AUTOSAR XML (schema 4-0-3)
standard types defined: UInt8
package /PATAC/Facility/DataTypes/Implementation
  unit NoUnit: factor-si-to-unit=1, offset-si-to-unit=0
package /PATAC/MSM/ComponentTypes
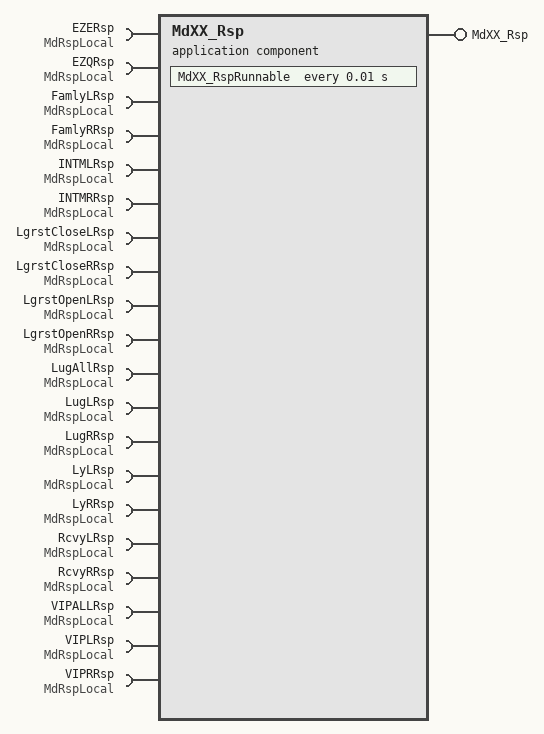
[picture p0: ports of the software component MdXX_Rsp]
  application sw component type MdXX_Rsp
    provide port MdXX_Rsp: provided-interface=MdXX_Rsp
      provided-com-specs:
        data-element=Md1_Rsp, init-value=0
        data-element=Md{10..19}_Rsp, init-value=0
        data-element=Md2_Rsp, init-value=0
        data-element=Md{20..29}_Rsp, init-value=0
        data-element=Md3_Rsp, init-value=0
        data-element=Md{30..32}_Rsp, init-value=0
        data-element=Md{4..9}_Rsp, init-value=0
    20 x require port, all with nonqueued-receiver-com-spec{data-element=Val, filter=data-filter-type=ALWAYS, init-value=0}, required-interface=MdRspLocal:
      EZERsp
      EZQRsp
      FamlyLRsp
      FamlyRRsp
      INTMLRsp
      INTMRRsp
      LgrstCloseLRsp
      LgrstCloseRRsp
      LgrstOpenLRsp
      LgrstOpenRRsp
      LugAllRsp
      LugLRsp
      LugRRsp
      LyLRsp
      LyRRsp
      RcvyLRsp
      RcvyRRsp
      VIPALLRsp
      VIPLRsp
      VIPRRsp
    behavior MdXX_Rsp_InternalBehavior
      timing event TMT_MdXX_RspRunnable: start-on-event=MdXX_RspRunnable, period=0.01
      runnable MdXX_RspRunnable
        data-receive-point-by-arguments:
          20 x access:
            REC_EZERsp_Val: accessed-variable=EZERsp.Val
            REC_EZQRsp_Val: accessed-variable=EZQRsp.Val
            REC_FamlyLRsp_Val: accessed-variable=FamlyLRsp.Val
            REC_FamlyRRsp_Val: accessed-variable=FamlyRRsp.Val
            REC_INTMLRsp_Val: accessed-variable=INTMLRsp.Val
            REC_INTMRRsp_Val: accessed-variable=INTMRRsp.Val
            REC_LgrstCloseLRsp_Val: accessed-variable=LgrstCloseLRsp.Val
            REC_LgrstCloseRRsp_Val: accessed-variable=LgrstCloseRRsp.Val
            REC_LgrstOpenLRsp_Val: accessed-variable=LgrstOpenLRsp.Val
            REC_LgrstOpenRRsp_Val: accessed-variable=LgrstOpenRRsp.Val
            REC_LugAllRsp_Val: accessed-variable=LugAllRsp.Val
            REC_LugLRsp_Val: accessed-variable=LugLRsp.Val
            REC_LugRRsp_Val: accessed-variable=LugRRsp.Val
            REC_LyLRsp_Val: accessed-variable=LyLRsp.Val
            REC_LyRRsp_Val: accessed-variable=LyRRsp.Val
            REC_RcvyLRsp_Val: accessed-variable=RcvyLRsp.Val
            REC_RcvyRRsp_Val: accessed-variable=RcvyRRsp.Val
            REC_VIPALLRsp_Val: accessed-variable=VIPALLRsp.Val
            REC_VIPLRsp_Val: accessed-variable=VIPLRsp.Val
            REC_VIPRRsp_Val: accessed-variable=VIPRRsp.Val
        data-send-points:
          32 x access:
            SEND_MdXX_Rsp_Md1_Rsp: accessed-variable=MdXX_Rsp.Md1_Rsp
            SEND_MdXX_Rsp_Md{10..19}_Rsp: accessed-variable=MdXX_Rsp.Md{10..19}_Rsp
            SEND_MdXX_Rsp_Md2_Rsp: accessed-variable=MdXX_Rsp.Md2_Rsp
            SEND_MdXX_Rsp_Md{20..29}_Rsp: accessed-variable=MdXX_Rsp.Md{20..29}_Rsp
            SEND_MdXX_Rsp_Md3_Rsp: accessed-variable=MdXX_Rsp.Md3_Rsp
            SEND_MdXX_Rsp_Md{30..32}_Rsp: accessed-variable=MdXX_Rsp.Md{30..32}_Rsp
            SEND_MdXX_Rsp_Md{4..9}_Rsp: accessed-variable=MdXX_Rsp.Md{4..9}_Rsp
  swc implementation MdXX_Rsp_Implementation: behavior=MdXX_Rsp_InternalBehavior
    code-descriptors:
      code Default: artifact-descriptors=autosar-engineering-object={short-label=Default, category=SWSRC}
package /PATAC/MSM/ModeAdjust/DataType
  impl type MdRspLocal1: category=VALUE, base-type=UInt8, sw-calibration-access=READ-ONLY, compu {0=MdRsp_None, 1=MdRsp_RecallSuccessfully, 2=MdRsp_RecallUnsuccessfully_LocalInterrupt, 3=MdRsp_RecallUnsuccessfully_Error, 4=MdRsp_RecallOngoing, 5=MdRsp_RecallHalt}, type-emitter=RTE
package /PATAC/MSM/ModeAdjust/PortInterface
  sender receiver interface MdRspLocal: invalidation-policy{data-element=Val, handle-invalid=DONT-INVALIDATE}
    data Val: type=MdRspLocal1
  sender receiver interface MdXX_Rsp
    32 x data, all with type=MdRspLocal1:
      Md1_Rsp
      Md{10..19}_Rsp
      Md2_Rsp
      Md{20..29}_Rsp
      Md3_Rsp
      Md{30..32}_Rsp
      Md{4..9}_Rsp
    invalidation-policys:
      data-element=Md1_Rsp, handle-invalid=DONT-INVALIDATE
      data-element=Md2_Rsp, handle-invalid=DONT-INVALIDATE
      data-element=Md5_Rsp, handle-invalid=DONT-INVALIDATE
      data-element=Md3_Rsp, handle-invalid=DONT-INVALIDATE
      data-element=Md7_Rsp, handle-invalid=DONT-INVALIDATE
      data-element=Md4_Rsp, handle-invalid=DONT-INVALIDATE
      data-element=Md6_Rsp, handle-invalid=DONT-INVALIDATE
      data-element=Md9_Rsp, handle-invalid=DONT-INVALIDATE
      data-element=Md8_Rsp, handle-invalid=DONT-INVALIDATE
      data-element=Md11_Rsp, handle-invalid=DONT-INVALIDATE
      data-element=Md10_Rsp, handle-invalid=DONT-INVALIDATE
      data-element=Md13_Rsp, handle-invalid=DONT-INVALIDATE
      data-element=Md12_Rsp, handle-invalid=DONT-INVALIDATE
      data-element=Md21_Rsp, handle-invalid=DONT-INVALIDATE
      data-element=Md14_Rsp, handle-invalid=DONT-INVALIDATE
      data-element=Md20_Rsp, handle-invalid=DONT-INVALIDATE
      data-element=Md15_Rsp, handle-invalid=DONT-INVALIDATE
      data-element=Md19_Rsp, handle-invalid=DONT-INVALIDATE
      data-element=Md16_Rsp, handle-invalid=DONT-INVALIDATE
      data-element=Md23_Rsp, handle-invalid=DONT-INVALIDATE
      data-element=Md17_Rsp, handle-invalid=DONT-INVALIDATE
      data-element=Md22_Rsp, handle-invalid=DONT-INVALIDATE
      data-element=Md18_Rsp, handle-invalid=DONT-INVALIDATE
      data-element=Md28_Rsp, handle-invalid=DONT-INVALIDATE
      data-element=Md24_Rsp, handle-invalid=DONT-INVALIDATE
      data-element=Md30_Rsp, handle-invalid=DONT-INVALIDATE
      data-element=Md25_Rsp, handle-invalid=DONT-INVALIDATE
      data-element=Md29_Rsp, handle-invalid=DONT-INVALIDATE
      data-element=Md26_Rsp, handle-invalid=DONT-INVALIDATE
      data-element=Md31_Rsp, handle-invalid=DONT-INVALIDATE
      data-element=Md32_Rsp, handle-invalid=DONT-INVALIDATE
      data-element=Md27_Rsp, handle-invalid=DONT-INVALIDATE
